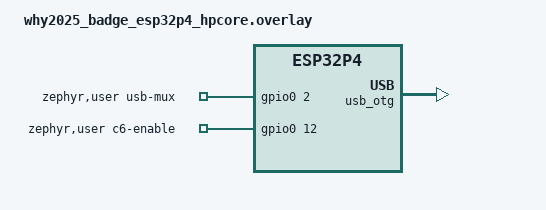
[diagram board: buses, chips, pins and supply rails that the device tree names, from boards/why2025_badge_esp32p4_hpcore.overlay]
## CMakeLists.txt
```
# SPDX-License-Identifier: GPL-3.0-or-later

cmake_minimum_required(VERSION 3.20.0)

find_package(Zephyr REQUIRED HINTS $ENV{ZEPHYR_BASE})
project(esp_sdr_pcap)

# USB: the CDC-ACM shell and DFU (app_usb.h); this app's vendor interface registers next to them.
include(${CMAKE_CURRENT_LIST_DIR}/../common/common.cmake)
# The radio over SDIO, the gapless stream's channelizer and the CPU clock, as the bridge has them.
include(${CMAKE_CURRENT_LIST_DIR}/../common/esdr_sdio_host.cmake)
include(${CMAKE_CURRENT_LIST_DIR}/../common/esdr_pfbq.cmake)
include(${CMAKE_CURRENT_LIST_DIR}/../common/app_clock.cmake)

target_include_directories(app PRIVATE src ../osmosdr/src ../../include ../ubertooth/src/upstream)
target_sources(app PRIVATE
  src/main.c
  src/radio.c
  src/survey.c
  src/narrow.c
  src/burst.c
  src/decoder.c
  src/output.c
  src/usb_pcap.c)

# The decoders and the stream's format: plain C, unit tested on native_sim (tests/unit/pcap_*,
# pcapng), at -O2 for their loops. The 802.15.4 PHY is lib/ieee802154's (no radio needed), the
# Bluetooth LE whitening and CRC the vendored Ubertooth tables (GPL-2.0-or-later).
set(PCAP_DSP
  src/follow.c
  src/pcapng.c
  src/records.c
  src/dec_ble.c
  src/dec_wpan.c
  src/dec_generic.c
  src/refine.c
  ${CMAKE_CURRENT_LIST_DIR}/../../lib/ieee802154/ieee154_phy.c
  ${CMAKE_CURRENT_LIST_DIR}/../ubertooth/src/upstream/bluetooth_le.c)
target_sources(app PRIVATE ${PCAP_DSP})
set_source_files_properties(${PCAP_DSP} PROPERTIES COMPILE_OPTIONS "-O2")
# The stream thread's work per sample (the channel mode's detector, the survey's assembler).
set_source_files_properties(src/narrow.c src/survey.c PROPERTIES COMPILE_OPTIONS "-O2")
```

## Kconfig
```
# SPDX-License-Identifier: GPL-3.0-or-later

mainmenu "ESP-SDR pcap"

menu "ESP-SDR pcap"

config APP_PCAP_BURSTS
	int "Burst buffers"
	default 48
	help
	  Buffers of a burst's samples (BURST_MAX_SAMPLES int16 pairs, 128 KiB
	  each) in PSRAM: bursts the channelizer assembles and the decoder has
	  yet to take.

config APP_PCAP_STREAM_CPU
	int "CPU of the stream thread"
	range 0 1
	default 1
	depends on SMP
	help
	  The channelizer's PIE state is per core and not saved on a
	  context switch: the stream thread is pinned before it starts.
	  The radio reader, USB, the shell and the work queues stay on
	  CPU 0 (SCHED_CPU_MASK_PIN_ONLY), where the interrupts and the
	  tick are. With the stream alone on CPU 1 and the decoders on
	  CPU 0, a 40 MS/s survey lost no bursts; the other way round the
	  reader and the stream overloaded CPU 0 (doc/pcap.md).

config APP_PCAP_DECODE_CPU
	int "CPU of the decoder and the generic analysis"
	range 0 1
	default 0
	depends on SMP

config APP_PCAP_GEN_WORKERS
	int "Generic analysis workers"
	range 1 2
	default 2 if SMP
	default 1
	help
	  Threads that analyse the bursts no decoder claimed, at the
	  lowest priority. The second is pinned to the stream thread's
	  CPU and takes the time the stream leaves there.

endmenu

rsource "../common/Kconfig"

# The USB device's identity (sample_usbd).
source "samples/subsys/usb/common/Kconfig.sample_usbd"

source "Kconfig.zephyr"
```

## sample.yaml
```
sample:
  name: ESP-SDR pcap
  description: >-
    An ESP32-P4 (WHY2025 badge, ESP32-P4-Function-EV-Board) demodulates and decodes the bursts
    its ESP32-C6 radio receives (Bluetooth LE, IEEE 802.15.4, any other as a burst record with
    its metadata) and streams them as pcapng over USB for Wireshark
common:
  tags: esp-sdr
  sysbuild: true
  platform_allow:
    - why2025_badge/esp32p4/hpcore
    - esp32p4_function_ev_board/esp32p4/hpcore
  integration_platforms:
    - why2025_badge/esp32p4/hpcore
    - esp32p4_function_ev_board/esp32p4/hpcore
tests:
  esp_sdr.pcap:
    build_only: true
```

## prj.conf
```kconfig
# SPDX-License-Identifier: GPL-3.0-or-later
#
# The ESP32-P4 as a burst sniffer: its ESP32-C6 radio over SDIO, the decoders, pcapng over USB.

CONFIG_GPIO=y
CONFIG_SDHC=y
CONFIG_SDIO_STACK=y
# The SDIO reader polls the radio's byte counter; idle, it sleeps a tick (100 us).
CONFIG_SYS_CLOCK_TICKS_PER_SEC=10000

# The decoders' floats; the burst buffers and scratch in PSRAM.
CONFIG_FPU=y
CONFIG_ESP_SPIRAM=y
CONFIG_HEAP_MEM_POOL_SIZE=16384
CONFIG_MAIN_STACK_SIZE=4096

# USB device on the OTG HS port: the shell on CDC-ACM, DFU with sysbuild/MCUboot, the pcapng
# stream on a vendor bulk IN endpoint (src/usb_pcap.c). Same PID as the other apps (host udev
# rules, west dfu); the host tool finds it by its product string.
CONFIG_USB_DEVICE_STACK_NEXT=y
CONFIG_UDC_DRIVER_HIGH_SPEED_SUPPORT_ENABLED=y
CONFIG_SAMPLE_USBD_PRODUCT="ESP-SDR pcap"
CONFIG_SAMPLE_USBD_PID=0x0005
CONFIG_USBD_LOG_LEVEL_WRN=y
CONFIG_UDC_DRIVER_LOG_LEVEL_WRN=y
CONFIG_USBD_CDC_ACM_CLASS=y
CONFIG_CDC_ACM_SERIAL_INITIALIZE_AT_BOOT=n
CONFIG_UART_LINE_CTRL=y
CONFIG_HWINFO=y
# Vendor requests wait for the radio's reply over SDIO in the USB thread.
CONFIG_USBD_THREAD_STACK_SIZE=4096
# The USB threads preempt the decoder where they share a core, not the system work queue that
# feeds the liveness watchdog (as in apps/micropython on the P4).
CONFIG_USBD_THREAD_PREEMPTIBLE=y
CONFIG_UDC_DWC2_THREAD_PREEMPTIBLE=y
# Below the stream thread (5) and the control queue (6), above the decoder (8): a long decode
# does not hold the stream's transfers back (on one core; with two the decoder has its own).
CONFIG_USBD_THREAD_PRIORITY=7
CONFIG_UDC_DWC2_THREAD_PRIORITY=7
CONFIG_USBD_DFU_TRANSFER_SIZE=1024
CONFIG_UDC_BUF_POOL_SIZE=4096

# The shell on CDC-ACM (west dfu confirms images with "mcuboot confirm"), logs on the console
# UART (the CH340 on the WHY2025 badge).
CONFIG_SHELL=y
CONFIG_SHELL_BACKEND_SERIAL=y
CONFIG_SHELL_LOG_BACKEND=n
CONFIG_SHELL_STACK_SIZE=3072
CONFIG_KERNEL_SHELL=y
CONFIG_MCUBOOT_SHELL=y
CONFIG_DEVICE_SHELL=n
CONFIG_DATE_SHELL=n
CONFIG_APP_LIVENESS_WATCHDOG=y
CONFIG_LOG=y
CONFIG_CBPRINTF_FP_SUPPORT=y
```

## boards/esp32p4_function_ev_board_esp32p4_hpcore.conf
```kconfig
# SPDX-License-Identifier: GPL-3.0-or-later
#
# The ESP32-P4-Function-EV-Board's default revision declares 8 MB of PSRAM (the V1.0B engineering
# board, revision 1.0.0, has 32): 32 burst buffers (4 MB) leave room for the PSRAM heap.
CONFIG_APP_PCAP_BURSTS=32
```

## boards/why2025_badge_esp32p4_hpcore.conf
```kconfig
# SPDX-License-Identifier: GPL-3.0-or-later
#
# The WHY2025 badge's 32 MB of PSRAM: 128 burst buffers (16 MB). The survey's 40 channels hold
# one each while open and the channelizer can keep the decoder waiting for some 12 ms (the radio's
# block pool), during which a busy band opens a few dozen bursts.
CONFIG_APP_PCAP_BURSTS=128

# Both HP cores (doc/pcap.md, "The P4"): CPU 1 the stream thread (channelizer, PIE) and a second
# generic analysis worker below it, CPU 0 the rest (the reader, USB, the decoders, the shell, the
# work queues). Pin-only: a thread nobody pins stays on CPU 0; IPIs only to the core a woken
# thread may run on.
CONFIG_SMP=y
CONFIG_SCHED_CPU_MASK=y
CONFIG_SCHED_CPU_MASK_PIN_ONLY=y
CONFIG_IPI_OPTIMIZE=y
```

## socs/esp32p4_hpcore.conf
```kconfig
# SPDX-License-Identifier: GPL-3.0-or-later
#
# The SoC turns the FPU on without sharing: the decoder thread, the channelizer and the shell
# (its float statistics) would clobber each other's float registers. Lazy switching (Zephyr
# decodes the trapping instruction from mtval, which the P4 fills).
CONFIG_FPU_SHARING=y
```

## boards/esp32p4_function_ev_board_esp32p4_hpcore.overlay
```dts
/*
 * SPDX-License-Identifier: GPL-3.0-or-later
 *
 * The ESP32-P4-Function-EV-Board's ESP32-P4: its USB 2.0 OTG HS port (USB-C) with the shell on
 * CDC-ACM, DFU and the pcapng stream; the C6 on sdhc1 (apps/osmosdr_serial with
 * CONFIG_APP_LINK_SDIO, installed by apps/c6_bootstrap).
 */

/ {
	chosen {
		esdr,link-sdio = &sdhc1;
		zephyr,shell-uart = &cdc_acm_uart0;
	};

	/* GPIO54 is the ESP32-C6's enable. */
	zephyr,user {
		c6-enable-gpios = <&gpio1 22 GPIO_ACTIVE_HIGH>;
	};
};

&esp_hosted_mcu {
	status = "disabled";
};

zephyr_udc0: &usb_otg {
	status = "okay";
	/*
	 * An IN endpoint is bulk capable only with a FIFO of a whole high-speed packet (512 bytes,
	 * 128 words). The endpoints take the FIFOs in order: CDC-ACM's notification endpoint the
	 * first (16 words, its packets are short), its data endpoint the second, the pcapng stream
	 * the third. With the RX FIFO (256) and EP0's (32) that is 816 of the controller's 896
	 * words (GHWCFG3), where three FIFOs of 128 would not fit.
	 */
	g-tx-fifo-size = <16 128 128 64 64 64 64>;

	cdc_acm_uart0: cdc_acm_uart0 {
		compatible = "zephyr,cdc-acm-uart";
		label = "ESP-SDR pcap shell";
	};
};

#include "../../micropython/boards/partitions_p4.dtsi"
```

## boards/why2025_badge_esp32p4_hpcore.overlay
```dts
/*
 * SPDX-License-Identifier: GPL-3.0-or-later
 *
 * The WHY2025 badge's ESP32-P4: USB-C port J8 on its OTG HS controller (GPIO2 low, the board's
 * default) with the shell on CDC-ACM, DFU and the pcapng stream; boot messages and logs on the
 * CH340 (UART0); the C6 on sdhc1 (apps/osmosdr_serial, gapless by default on this board).
 */

/ {
	chosen {
		esdr,link-sdio = &sdhc1;
		zephyr,shell-uart = &cdc_acm_uart0;
	};

	/* GPIO2 hands USB-C port J8 to the ESP32-C6; GPIO12 is its enable. */
	zephyr,user {
		usb-mux-gpios = <&gpio0 2 GPIO_ACTIVE_HIGH>;
		c6-enable-gpios = <&gpio0 12 GPIO_ACTIVE_HIGH>;
	};
};

/* The ESP32-C6 runs the radio firmware, not esp-hosted, whose driver would reset it. */
&esp_hosted_mcu {
	status = "disabled";
};

zephyr_udc0: &usb_otg {
	status = "okay";
	/*
	 * An IN endpoint is bulk capable only with a FIFO of a whole high-speed packet (512 bytes,
	 * 128 words). The endpoints take the FIFOs in order: CDC-ACM's notification endpoint the
	 * first (16 words, its packets are short), its data endpoint the second, the pcapng stream
	 * the third. With the RX FIFO (256) and EP0's (32) that is 816 of the controller's 896
	 * words (GHWCFG3), where three FIFOs of 128 would not fit.
	 */
	g-tx-fifo-size = <16 128 128 64 64 64 64>;

	cdc_acm_uart0: cdc_acm_uart0 {
		compatible = "zephyr,cdc-acm-uart";
		label = "ESP-SDR pcap shell";
	};
};

#include "../../micropython/boards/partitions_p4.dtsi"
```

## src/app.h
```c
/*
 * SPDX-License-Identifier: GPL-3.0-or-later
 *
 * What the parts of apps/pcap share (doc/pcap.md): the capture's settings, the time base, the
 * burst pool and the decoder's queue, the counters. main.c owns the settings and changes them
 * only while no capture runs.
 */

#ifndef APP_H_
#define APP_H_

#include <stdbool.h>
#include <stdint.h>

#include "burst.h"
#include "esdr_proto.h"
#include "pcap_proto.h"

/* The capture's settings: what the host or the shell set, taken at each start. */
struct app_cfg {
	/* enum pcap_mode and PCAP_MODE_F_*; the alternation's dwell times (both 0: none). */
	uint16_t mode, mode_flags;
	uint32_t survey_ms, channel_ms;
	/* The survey's centre and the channel mode's frequency and rate, as asked for. */
	uint64_t survey_hz, channel_hz;
	uint32_t channel_rate_hz;
	/* Receive gain index or ESDR_GAIN_AUTO. */
	uint16_t rx_gain;
	/* The channelizer: M, the detector's opening ratio, the channels kept. */
	uint16_t channels;
	float open_ratio;
	uint32_t mask[3];
	/* The C6's gapless settings (ESDR_REQ_SET_GAPLESS as the host sent it). */
	struct esdr_gapless_cfg gapless;
	/* What runs over the bursts. */
	struct pcap_decoders dec;
};

extern struct app_cfg app_cfg;

/* ---- time ---- */

/* The host's time: nanoseconds since the Unix epoch now (PCAP_REQ_SET_TIME). */
void timebase_set(uint64_t epoch_ns);
/* A run's first block: its time on the stream's axis (ns) is now. */
void timebase_anchor(uint64_t axis_ns);
/* The host time of a time on the stream's axis (the radio's clock: 80 or 40 MS/s, or the
 * channel).
 */
uint64_t timebase_ns(uint64_t axis_ns);
/* The host time now. */
uint64_t timebase_now_ns(void);

/* Sample @p m of a stream at @p rate_hz on the axis, ns (the rates divide 10^9). */
static inline uint64_t axis_ns(uint64_t m, uint32_t rate_hz)
{
	return m * (1000000000U / rate_hz);
}

/* ---- the burst pool (burst.c) ---- */

/* A free burst with its buffer, NULL when none; back with burst_put(). Any thread. */
struct burst *burst_get(void);
void burst_put(struct burst *b);
uint32_t burst_free_count(void);

/* ---- the decoder (decoder.c) ---- */

void decoder_init(void);
/* A closed burst for the decoder: 0, or -ENOSPC (the caller still owns it). */
int decoder_put(struct burst *b);
/* A wideband burst the C6 reported (a run of its width records): its records' sums. */
struct wide_run {
	/* The radio's centre, and the run's first and last pair on its 80 MS/s axis. */
	uint64_t centre_hz;
	uint64_t index, end;
	float r1_i, r1_q;
	int16_t power_dbfs_x10;
	uint8_t gain;
	uint16_t records;
};
int decoder_put_wide(const struct wide_run *w);
/* Bursts queued and waiting. */
uint32_t decoder_backlog(void);
/*
 * Bluetooth LE access addresses the decoder looks for besides the advertising one
 * (PCAP_REQ_ADD_AA): @p op 0 adds @p aa with @p crc_init, 1 removes it, 2 forgets all (the
 * learnt ones too). 0, -ENOSPC or -EINVAL.
 */
int decoder_aa(uint16_t op, uint32_t aa, uint32_t crc_init);

/* ---- the stream thread and its modes (survey.c, narrow.c) ---- */

/*
 * The stream thread to the survey of the gapless segments around @p centre_hz (the radio's
 * centre) at @p in_rate_hz (the C6's rate: ESDR_GAPLESS_RATE_HZ, or half with
 * ESDR_GAPLESS_F_HALF), to the channel mode at @p freq_hz and @p rate_hz, or to idle; what was
 * open goes to the decoder, cut. Called from the control thread: they wait for the stream
 * thread. 0 or a negative errno.
 */
int survey_start(uint64_t centre_hz, uint32_t in_rate_hz);
/* Whether the survey can run its bank at @p in_rate_hz: 0, -EINVAL or -ENOMEM. */
int survey_check(uint32_t in_rate_hz);
int stream_narrow(uint64_t freq_hz, uint32_t rate_hz);
void survey_stop(void);
/* The radio's sink (radio.h) while a mode runs. */
void survey_block(uint8_t *blk);

/* The channel mode's parts, run by the stream thread (narrow.c). */
int narrow_start(uint64_t freq_hz, uint32_t rate_hz);
void narrow_stop(void);
void narrow_block(const uint8_t *blk);

/* ---- the follow mode (main.c) ---- */

/*
 * The decoder thread found 802.15.4 on @p channel, worth @p points (follow.h), in a burst of the
 * survey or of the channel mode. Nothing unless the capture follows.
 */
void follow_report(int channel, uint32_t points, bool from_survey);

/* ---- counters ---- */

/* Generic analysis workers (decoder.c): a second one goes on the stream's core. */
#define APP_GEN_WORKERS CONFIG_APP_PCAP_GEN_WORKERS

struct app_stats {
	uint32_t seg_blocks, seg_dropped, other_blocks;
	uint64_t pairs, chan_cycles;
	uint32_t bursts, bursts_lost, bursts_wide;
	uint32_t decoded;
	uint64_t dec_cycles;
	uint64_t channel_samples;
	uint32_t channel_gaps, c6_wide;
	/* generic and generic_cycles per worker: one writer each. */
	uint32_t generic[APP_GEN_WORKERS], generic_skipped, generic_wide;
	uint64_t generic_cycles[APP_GEN_WORKERS];
	/* The follow mode: the survey's sightings per channel (11 to 26), stays on a channel. */
	uint32_t follow_sights[16], follow_hops;
};

extern struct app_stats app_stats;

#endif /* APP_H_ */
```

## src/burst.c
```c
/*
 * SPDX-License-Identifier: GPL-3.0-or-later
 *
 * The burst pool (app.h): CONFIG_APP_PCAP_BURSTS buffers of BURST_MAX_SAMPLES int16 pairs in
 * PSRAM, handed out by a queue of the free ones.
 */

#include <zephyr/kernel.h>

#include "app.h"
#include "dec_util.h"

/* PSRAM: EXT_RAM_BSS_ATTR is empty on the ESP32-P4, whose linker script still puts the section
 * there (apps/micropython/cmod/esdr_defs.h).
 */
#define PSRAM __attribute__((section(".ext_ram.bss")))

static int16_t mem[CONFIG_APP_PCAP_BURSTS][2U * BURST_MAX_SAMPLES] __aligned(16) PSRAM;
static struct burst bursts[CONFIG_APP_PCAP_BURSTS];
K_MSGQ_DEFINE(free_q, sizeof(struct burst *), CONFIG_APP_PCAP_BURSTS, 4);

struct burst *burst_get(void)
{
	struct burst *b;

	if (k_msgq_get(&free_q, &b, K_NO_WAIT) != 0) {
		return NULL;
	}
	*b = (struct burst){.iq = b->iq};
	return b;
}

void burst_put(struct burst *b)
{
	(void)k_msgq_put(&free_q, &b, K_NO_WAIT);
}

uint32_t burst_free_count(void)
{
	return k_msgq_num_used_get(&free_q);
}

int16_t burst_dbfs_x10(float power)
{
	return dec_dbfs_x10(power);
}

static int burst_pool_init(void)
{
	for (unsigned int i = 0; i < CONFIG_APP_PCAP_BURSTS; i++) {
		struct burst *b = &bursts[i];

		b->iq = mem[i];
		(void)k_msgq_put(&free_q, &b, K_NO_WAIT);
	}
	return 0;
}
SYS_INIT(burst_pool_init, APPLICATION, 0);
```

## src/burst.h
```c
/*
 * SPDX-License-Identifier: GPL-3.0-or-later
 *
 * A burst: one channel's samples from the detector's opening to its closing (doc/pcap.md).
 * The assembler (burst.c, the channelizer thread) fills one from the detector's events; the
 * decoder thread reads it. Plain C: the decoders and their tests on native_sim use this header
 * without Zephyr.
 */

#ifndef BURST_H_
#define BURST_H_

#include <stdbool.h>
#include <stddef.h>
#include <stdint.h>

/* Frames (complex samples) a burst holds at most: 8.2 ms at 4 MS/s. */
#define BURST_MAX_SAMPLES 32768U
/* Adjacent channels open at once that make a wideband signal (the pool's size is
 * CONFIG_APP_PCAP_BURSTS). */
#define BURST_WIDE_MIN 6U

/* struct burst.flags */
/* Cut at BURST_MAX_SAMPLES while the channel stayed open. */
#define BURST_F_TRUNCATED 0x0001U
/* Part of a wideband signal: no samples kept (n is 0), only the metadata. */
#define BURST_F_WIDEBAND  0x0002U
/* Frames of the filterbank's transient among the samples (a gap in the input). */
#define BURST_F_TRANSIENT 0x0004U
/* A neighbouring channel was open at the same time. */
#define BURST_F_NEIGHBOUR 0x0008U
/* The C6 dropped windows before this burst (ESDR_SEG_DROPPED). */
#define BURST_F_DROPPED   0x0010U
/* Samples at the receiver's full scale. */
#define BURST_F_CLIPPED   0x0020U
/* Still open when the capture stopped. */
#define BURST_F_CUT       0x0040U
/* Ended at a hole in the radio's stream (the C6 kept nothing for a while): what follows is
 * another burst. */
#define BURST_F_HOLE      0x0080U
/* A decoder emitted a packet from it (the decoder thread's: no generic analysis follows). */
#define BURST_F_CLAIMED   0x0100U
/* gate_snr and gate_narrow are set (the decoder thread's). */
#define BURST_F_GATED     0x0200U

struct burst {
	/* The channelizer's channel index and count, the channel's rate and centre frequency. */
	uint16_t chan, channels;
	uint32_t rate_hz;
	uint64_t freq_hz;
	/*
	 * The first sample's frame index on the channel's absolute grid (its pair index is
	 * m0 * D, D = channels / 2, on the C6's axis: 80 MS/s, or 40 with ESDR_GAPLESS_F_HALF): the
	 * decoders and the combination of two neighbours go by it.
	 */
	uint64_t m0;
	/* Samples in iq (frames), their first and last one that the detector found loud. */
	uint32_t n, loud_from, loud_to;
	/* The detector's floor and the highest block power of the burst, output units squared
	 * (a full-scale carrier, 512 raw units, is 16384 in the samples: 16384^2 here). */
	float floor, power;
	/* BURST_F_* */
	uint16_t flags;
	/* Receive gain index of the segment that opened it (ESDR_SEG_GAIN_AUTO: automatic). */
	uint8_t gain;
	/* Reference count, the decoder thread's (a burst held for its neighbour). */
	uint8_t ref;
	/* For wideband bursts: the lowest and highest adjacent channel open with this one. */
	uint16_t wide_lo, wide_hi;
	/* The decoder thread's look at the loud part (BURST_F_GATED): power above the floor over
	 * the floor, the correlation one sample apart over that power. */
	float gate_snr, gate_narrow;
	/* n interleaved I, Q samples, 4-byte aligned, in the pool's buffer. */
	int16_t *iq;
};

/* dB relative to the receiver's full scale, times 10, of a power in output units squared. */
int16_t burst_dbfs_x10(float power);

#endif /* BURST_H_ */
```

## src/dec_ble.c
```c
/*
 * SPDX-License-Identifier: GPL-3.0-or-later
 *
 * The Bluetooth LE decoder of apps/pcap (decode.h, doc/pcap.md "Decoders"): LE 1M and LE 2M
 * packets in a closed burst at 4 or 2 MS/s, the algorithm of apps/chancap/tools/ble_pcap.py. An
 * FM discriminator (dec_step(), a binary angle a sample) summed over a symbol at every sampling
 * phase, the access addresses looked for at every position whatever the carrier offset, the
 * bits sliced at the preamble's level, dewhitened and CRC checked with the vendored upstream
 * apps/ubertooth/src/upstream/bluetooth_le.c (its directory on the include path, its source
 * linked in). Plain C, no Zephyr: tests/unit/pcap_ble runs it on native_sim.
 *
 * The search runs per sampling phase, in sample order, in two steps. The coarse step, at every
 * position (of every other phase at 4 samples a symbol): each soft symbol sliced once against
 * the mean of the 32 symbols from it on (all of them signal where an access address starts up
 * to 31 symbols before, whatever precedes the packet), the last 32 decisions compared with
 * every address. Where an address comes within max_errors + GATE_SLACK bits (and
 * |ones - zeros| / 8 more for an unbalanced one), the fine step is ble_pcap.py's find_aa() at
 * the positions from there to one symbol past the first match: the normalised correlation of
 * the 32 soft symbols with the address's +-1 pattern and their bit errors against the window's
 * own midpoint. The best match with at most max_errors errors is taken (fewest errors, then
 * highest correlation). Matches are taken in time order: ble_pcap.py takes the best match of
 * the whole rest of a capture, which can skip a packet before a better one.
 */

#include <errno.h>
#include <stdbool.h>
#include <stdint.h>
#include <string.h>

#include "bluetooth_le.h"
#include "dec_util.h"
#include "decode.h"

#define SYM_RATE_1M 1000000U
#define SYM_RATE_2M 2000000U

/* Symbols of the preambles, of the access address, and of the shortest packet after the
 * preamble (address, PDU header, CRC). */
#define PRE_1M     8U
#define PRE_2M     16U
#define AA_SYMS    32U
#define MIN_SYMS   (32U + 16U + 24U)
/* Preamble symbols before the address whose mean is the slicing level: alternating, so the
 * Gaussian filter's intersymbol interference cancels. */
#define LEVEL_SYMS 6U
/* The coarse step's bit errors beyond max_errors (its level is not the window's midpoint). */
#define GATE_SLACK 4U

/* Longer bursts are refused: sample indices stay well within 32 bits. */
#define N_MAX (1U << 24)

/* The RF channels: 2402 MHz + 2 MHz c for c = 0 .. 39, a frequency within 500 kHz. */
#define RF_BASE_HZ 2402000000LL
#define RF_STEP_HZ 2000000LL
#define RF_TOL_HZ  500000LL
#define RF_COUNT   40

/* CONNECT_IND: advertising PDU type 5, a payload of InitA, AdvA and 22 bytes of LLData whose
 * access address and CRCInit sit at these offsets of dec_ble_pkt.air (ubt_le.h). */
#define PDU_CONNECT_IND 5U
#define CONNECT_LEN     34U
#define AIR_CONN_AA     18U
#define AIR_CONN_CRC    22U

/*
 * LE 1M packets whose samples LE 2M skips, at most: one takes 80 symbols or more, 320 samples
 * at 4 MS/s (the only rate with LE 2M).
 */
#define CLAIMS(n) ((n) / 256U + 2U)

/* A configured access address as the search uses it. */
struct pat {
	uint32_t aa;
	uint32_t crc_init;
	/* Its ones, zeros, ones - zeros, and 1024 - (ones - zeros)^2 (32^2 / 32 times the
	 * variance of its +-1 pattern). */
	int32_t n1, n0, psum;
	int64_t varp;
	/* The coarse step's bit errors at most. */
	uint32_t gate;
};

/* One PHY's view of the burst: the symbol sums per sampling phase. */
struct pass {
	const int16_t *s[4];
	uint32_t k[4];
	uint32_t sps;
	uint32_t pre;
	uint32_t sym_rate;
	enum dec_ble_phy phy;
};

/* Samples [from, to) of an LE 1M packet: LE 2M looks for nothing there. */
struct claim {
	int32_t from, to;
};

struct ctx {
	const struct burst *b;
	const struct dec_ble_cfg *cfg;
	struct pat pat[DEC_BLE_AA_MAX];
	unsigned int npat;
	/* The channel's centre, MHz, for le_dewhiten(). */
	unsigned int mhz;
	/* n binary angles (the last one 0), n symbol sums, the claims. */
	int16_t *d;
	int16_t *sums;
	struct claim *claims;
	uint32_t nclaims, claims_max;
	dec_ble_emit emit;
	void *user;
	int count;
};

/* A position the fine step accepted: phase, symbol, address, bit errors, correlation (Q14). */
struct match {
	uint32_t p, k;
	const struct pat *pat;
	uint32_t errors;
	int32_t r;
};

/* In the coarse step's loop: inline at -Os too. */
static inline __attribute__((always_inline)) uint32_t popcount32(uint32_t v)
{
	v = v - ((v >> 1) & 0x55555555U);
	v = (v & 0x33333333U) + ((v >> 2) & 0x33333333U);
	v = (v + (v >> 4)) & 0x0F0F0F0FU;
	return (v * 0x01010101U) >> 24;
}

/* CRCInit as the CONNECT_IND carries it to the start state of btle_crcgen_lut(): bit reversed. */
static uint32_t rev24(uint32_t v)
{
	uint32_t r = 0;

	for (unsigned int i = 0; i < 24U; i++) {
		r |= ((v >> i) & 1U) << (23U - i);
	}
	return r;
}

static uint32_t isqrt64(uint64_t v)
{
	uint64_t r = 0, bit = 1ULL << 62;

	while (bit > v) {
		bit >>= 2;
	}
	while (bit != 0U) {
		if (v >= r + bit) {
			v -= r + bit;
			r = (r >> 1) + bit;
		} else {
			r >>= 1;
		}
		bit >>= 2;
	}
	return (uint32_t)r;
}

int dec_ble_rf_channel(uint64_t freq_hz)
{
	int64_t d, c, dev;

	if (freq_hz > (uint64_t)INT64_MAX / 2U) {
		return -1;
	}
	d = (int64_t)freq_hz - RF_BASE_HZ + RF_STEP_HZ / 2;
	if (d < 0) {
		return -1;
	}
	c = d / RF_STEP_HZ;
	dev = d - c * RF_STEP_HZ - RF_STEP_HZ / 2;
	if (c >= RF_COUNT || dev <= -RF_TOL_HZ || dev >= RF_TOL_HZ) {
		return -1;
	}
	return (int)c;
}

size_t dec_ble_scratch(uint32_t n)
{
	/* Alignment, the claims, the angles and the symbol sums. */
	return 4U + (size_t)CLAIMS(n) * sizeof(struct claim) + 2U * (size_t)n * sizeof(int16_t);
}

static unsigned int patterns(const struct dec_ble_cfg *cfg, struct pat *pt)
{
	unsigned int n = 0;

	for (unsigned int i = 0; i < cfg->aa_count; i++) {
		int32_t ones = (int32_t)popcount32(cfg->aa[i].aa);
		int32_t psum = 2 * ones - 32;

		/* A constant pattern correlates with nothing. */
		if (ones == 0 || ones == 32) {
			continue;
		}
		pt[n].aa = cfg->aa[i].aa;
		pt[n].crc_init = cfg->aa[i].crc_init & 0xFFFFFFU;
		pt[n].n1 = ones;
		pt[n].n0 = 32 - ones;
		pt[n].psum = psum;
		pt[n].varp = 1024 - psum * psum;
		pt[n].gate =
			cfg->max_errors + GATE_SLACK + (uint32_t)(psum < 0 ? -psum : psum) / 8U;
		n++;
	}
	return n;
}

/* The phase step from every sample to the next: one dec_step() a sample. */
static void angles(const struct burst *b, int16_t *d)
{
	const int16_t *iq = b->iq;
	uint32_t i;

	for (i = 0; i + 1U < b->n; i++, iq += 2) {
		/* +pi (32768) wraps to -pi: the same angle. */
		d[i] = (int16_t)dec_step(iq[0], iq[1], iq[2], iq[3]);
	}
	d[b->n - 1U] = 0;
}

/*
 * ble_pcap.py's symbol_sums() and phase split: the angles summed over a symbol (sps of them)
 * from every sample on, divided by sps (rounded, to stay within int16), the sums of the
 * samples p, p + sps, p + 2 sps, ... in a row for phase p.
 */
static void symbol_sums(struct ctx *c, struct pass *ps)
{
	const uint32_t sps = ps->sps;
	const uint32_t shift = sps == 4U ? 2U : 1U;
	const int32_t half = (int32_t)(sps >> 1);
	const uint32_t total = c->b->n - sps;
	const uint32_t stride = (total + sps - 1U) / sps;
	const int16_t *d = c->d;
	int16_t *const sums = c->sums;
	int32_t run = 0;
	uint32_t i, j, k, p;

	for (p = 0; p < sps; p++) {
		ps->s[p] = sums + p * stride;
		ps->k[p] = total > p ? (total - p + sps - 1U) / sps : 0U;
	}
	for (i = 0; i < sps; i++) {
		run += d[i];
	}
	for (j = 0, k = 0; j < total; k++) {
		for (p = 0; p < sps && j < total; p++, j++) {
			sums[p * stride + k] = (int16_t)((run + half) >> shift);
			run += d[j + sps] - d[j];
		}
	}
}

/*
 * find_aa() at one position: the normalised correlation (Q14) of the 32 soft symbols from @p s
 * with the address's +-1 pattern, and the bit errors against the window's own midpoint (the
 * middle between the mean of the symbols where the address has ones and that where it has
 * zeros), returned. A flat window matches nothing.
 */
static uint32_t exact(const int16_t *s, const struct pat *pt, int32_t *r)
{
	int32_t s1 = 0, a1 = 0, a0, num, den;
	int64_t s2 = 0, c, var;
	uint32_t errors = 0, i;

	for (i = 0; i < AA_SYMS; i++) {
		int32_t v = s[i];

		s1 += v;
		s2 += (int64_t)v * v;
		if (((pt->aa >> i) & 1U) != 0U) {
			a1 += v;
		}
	}
	var = 32 * s2 - (int64_t)s1 * s1;
	if (var <= 0) {
		*r = 0;
		return AA_SYMS;
	}
	a0 = s1 - a1;
	c = 32 * (int64_t)(a1 - a0) - (int64_t)pt->psum * s1;
	*r = (int32_t)(c * 16384 / (int64_t)isqrt64((uint64_t)var * (uint64_t)pt->varp));
	num = a1 * pt->n0 + a0 * pt->n1;
	den = 2 * pt->n1 * pt->n0;
	for (i = 0; i < AA_SYMS; i++) {
		errors += (uint32_t)(s[i] * den > num) ^ ((pt->aa >> i) & 1U);
	}
	return errors;
}

/*
 * The fine step from sample position @p x0 (phase x0 % sps, symbol x0 / sps) to one symbol past
 * the first position that matches; positions up to @p done were looked at before. True with
 * the best match in @p best.
 */
static bool fine(const struct ctx *c, const struct pass *ps, int32_t x0, uint32_t k0min,
		 int32_t *done, struct match *best)
{
	const int32_t sps = (int32_t)ps->sps;
	int32_t x = x0 > *done ? x0 : *done + 1;
	int32_t xend = x0 + sps - 1;
	bool found = false;

	for (; x <= xend; x++) {
		uint32_t p = (uint32_t)x % ps->sps, k = (uint32_t)x / ps->sps;

		*done = x;
		if (k < k0min || ps->k[p] < MIN_SYMS || k > ps->k[p] - MIN_SYMS) {
			continue;
		}
		for (unsigned int j = 0; j < c->npat; j++) {
			int32_t r;
			uint32_t e = exact(ps->s[p] + k, &c->pat[j], &r);

			if (e > c->cfg->max_errors) {
				continue;
			}
			if (!found) {
				xend = x + sps - 1;
			}
			if (!found || e < best->errors || (e == best->errors && r > best->r)) {
				best->p = p;
				best->k = k;
				best->pat = &c->pat[j];
				best->errors = e;
				best->r = r;
				found = true;
			}
		}
	}
	return found;
}

/*
 * @p nbytes bytes of the symbols from @p s, a one where a symbol lies above the level
 * num / den, the first symbol on air in each byte's bit 7 (as le_dewhiten() takes them).
 */
static void slice(const int16_t *s, int32_t num, int32_t den, uint8_t *out, uint32_t nbytes)
{
	for (uint32_t i = 0; i < nbytes; i++, s += 8) {
		uint32_t v = 0;

		for (uint32_t j = 0; j < 8U; j++) {
			v = (v << 1) | (uint32_t)(s[j] * den > num);
		}
		out[i] = (uint8_t)v;
	}
}

/* Mean I^2 + Q^2 over samples [from, to) of the burst. */
static float power(const struct burst *b, int32_t from, int32_t to)
{
	uint64_t acc = 0;

	if (from < 0) {
		from = 0;
	}
	if (to > (int32_t)b->n) {
		to = (int32_t)b->n;
	}
	if (to <= from) {
		return 0.0f;
	}
	for (int32_t i = from; i < to; i++) {
		int32_t vi = b->iq[2 * i], vq = b->iq[2 * i + 1];

		acc += (uint32_t)(vi * vi) + (uint32_t)(vq * vq);
	}
	return (float)acc / (float)(to - from);
}

static uint32_t le_get(const uint8_t *p, unsigned int bytes)
{
	uint32_t v = 0;

	for (unsigned int i = 0; i < bytes; i++) {
		v |= (uint32_t)p[i] << (8U * i);
	}
	return v;
}

/*
 * The packet whose access address the fine step found: sliced at the mean of the preamble's
 * last LEVEL_SYMS symbols (at the window's midpoint without room for them), the header
 * dewhitened for the length, then all of it; the CRC checked, the packet emitted unless its
 * CRC failed and bad ones are not kept. Returns the symbol the search goes on from: after the
 * packet, or after the address when the CRC failed (its length is not to be trusted) or the
 * burst ends before the packet does (ble_pcap.py's decode()).
 */
static uint32_t decode(struct ctx *c, const struct pass *ps, const struct match *m)
{
	const struct pat *pt = m->pat;
	const int16_t *s = ps->s[m->p] + m->k;
	const uint32_t avail = ps->k[m->p] - m->k;
	const uint32_t sps = ps->sps;
	struct dec_ble_pkt pkt;
	int32_t num = 0, den, x, end;
	uint32_t rx = 0, len, nbytes, i;
	uint8_t hdr[2];
	bool trusted;

	if (m->k >= LEVEL_SYMS) {
		for (i = 1; i <= LEVEL_SYMS; i++) {
			num += s[-(int32_t)i];
		}
		den = (int32_t)LEVEL_SYMS;
	} else {
		int32_t a1 = 0, a0 = 0;

		for (i = 0; i < AA_SYMS; i++) {
			if (((pt->aa >> i) & 1U) != 0U) {
				a1 += s[i];
			} else {
				a0 += s[i];
			}
		}
		num = a1 * pt->n0 + a0 * pt->n1;
		den = 2 * pt->n1 * pt->n0;
	}
	for (i = 0; i < AA_SYMS; i++) {
		rx |= (uint32_t)(s[i] * den > num) << i;
	}
	slice(s + AA_SYMS, num, den, hdr, 2U);
	le_dewhiten(hdr, 2U, c->mhz);
	len = hdr[1];
	nbytes = 2U + len + 3U;
	if (AA_SYMS + 8U * nbytes > avail) {
		return m->k + AA_SYMS;
	}

	memset(&pkt, 0, sizeof(pkt));
	pkt.phy = ps->phy;
	pkt.aa = pt->aa;
	pkt.aa_errors = (uint8_t)popcount32(rx ^ pt->aa);
	for (i = 0; i < 4U; i++) {
		pkt.air[i] = (uint8_t)(pt->aa >> (8U * i));
	}
	slice(s + AA_SYMS, num, den, pkt.air + 4, nbytes);
	le_dewhiten(pkt.air + 4, nbytes, c->mhz);
	pkt.len = (uint16_t)(4U + nbytes);
	pkt.crc_checked = pt->crc_init != 0U;
	if (pkt.crc_checked) {
		pkt.crc_ok = btle_crcgen_lut(rev24(pt->crc_init), pkt.air + 4, (int)(2U + len)) ==
			     le_get(pkt.air + 6U + len, 3U);
	}
	x = (int32_t)(m->p + m->k * sps);
	pkt.start = x - (int32_t)(ps->pre * sps);
	end = x + (int32_t)((AA_SYMS + 8U * nbytes) * sps);
	/* The level is a mean angle a sample: times sps a symbol. */
	pkt.offset_hz = (int32_t)lrintf(
		dec_angle_hz((float)num / (float)den * (float)sps, (float)ps->sym_rate));
	pkt.power = power(c->b, pkt.start, end);
	if (pt->aa == DEC_BLE_ADV_AA && pkt.crc_ok && (pkt.air[4] & 0x0FU) == PDU_CONNECT_IND &&
	    len >= CONNECT_LEN) {
		pkt.conn_aa = le_get(pkt.air + AIR_CONN_AA, 4U);
		pkt.conn_crc_init = le_get(pkt.air + AIR_CONN_CRC, 3U);
	}

	trusted = !pkt.crc_checked || pkt.crc_ok;
	if (trusted && ps->phy == DEC_BLE_PHY_1M && c->nclaims < c->claims_max) {
		c->claims[c->nclaims].from = pkt.start;
		c->claims[c->nclaims].to = end;
		c->nclaims++;
	}
	if (trusted || c->cfg->keep_bad) {
		c->count++;
		if (c->emit != NULL) {
			c->emit(&pkt, c->user);
		}
	}
	return trusted ? m->k + AA_SYMS + 8U * nbytes : m->k + AA_SYMS;
}

/*
 * The coarse step of one sampling phase, resumable: the next symbol to push, the first push
 * that completes a window to test, the end (an address from symbol K - 72 on leaves no room
 * for a packet, so pushes stop at K - 41), the last 32 decisions (the newest in bit 31: the
 * address's bit 0, first on air, in bit 0), the sum of the 32 symbols from the next one on,
 * and the pending hit: the sample position of its window's first symbol, -1 for none.
 */
struct coarse {
	const int16_t *s;
	uint32_t p;
	uint32_t k, ktest, kend;
	uint32_t reg;
	int32_t fsum;
	int32_t hit;
};

static void coarse_start(struct coarse *cs, const struct pass *ps, uint32_t p, uint32_t k0)
{
	const uint32_t kn = ps->k[p];

	cs->s = ps->s[p];
	cs->p = p;
	cs->k = k0;
	cs->ktest = k0 + AA_SYMS - 1U;
	cs->kend = kn >= MIN_SYMS ? kn - (MIN_SYMS - AA_SYMS) : 0U;
	cs->reg = 0;
	cs->fsum = 0;
	cs->hit = -1;
	if (k0 < cs->kend) {
		for (uint32_t i = 0; i < AA_SYMS; i++) {
			cs->fsum += cs->s[k0 + i];
		}
	}
}

/* One symbol into the decisions: above the mean of the 32 from it on, or not. */
#define COARSE_PUSH()                                                                              \
	do {                                                                                       \
		int32_t v_ = s[k];                                                                 \
                                                                                                   \
		reg = (reg >> 1) | ((uint32_t)(32 * v_ > fsum) << 31);                             \
		fsum += s[k + AA_SYMS] - v_;                                                       \
		k++;                                                                               \
	} while (0)

/* The phase's next hit: the next window within an address's gate (cs->hit, -1 at the end). */
static void coarse_next(struct coarse *cs, const struct ctx *c, uint32_t sps)
{
	const int16_t *s = cs->s;
	const uint32_t kend = cs->kend;
	uint32_t k = cs->k, reg = cs->reg;
	int32_t fsum = cs->fsum;

	cs->hit = -1;
	while (k < kend && k < cs->ktest) {
		COARSE_PUSH();
	}
	if (c->npat == 1U) {
		const uint32_t aa = c->pat[0].aa, gate = c->pat[0].gate;

		while (k < kend) {
			COARSE_PUSH();
			if (popcount32(reg ^ aa) <= gate) {
				cs->hit = (int32_t)(cs->p + (k - AA_SYMS) * sps);
				break;
			}
		}
	} else {
		while (k < kend && cs->hit < 0) {
			COARSE_PUSH();
			for (unsigned int j = 0; j < c->npat; j++) {
				if (popcount32(reg ^ c->pat[j].aa) <= c->pat[j].gate) {
					cs->hit = (int32_t)(cs->p + (k - AA_SYMS) * sps);
					break;
				}
			}
		}
	}
	cs->k = k;
	cs->reg = reg;
	cs->fsum = fsum;
}

/* Every scanned phase from symbol @p k0 on, each to its first hit. */
static void coarse_restart(struct coarse *cs, uint32_t nc, uint32_t step, const struct ctx *c,
			   const struct pass *ps, uint32_t k0)
{
	for (uint32_t i = 0; i < nc; i++) {
		coarse_start(&cs[i], ps, i * step, k0);
		coarse_next(&cs[i], c, ps->sps);
	}
}

/*
 * Every packet of one PHY, in time order (see the top of the file): the phases' coarse hits
 * merged in sample order, the fine step at each. At 4 samples a symbol the coarse step scans
 * every other phase (a symbol sum one sample off the eye's centre still decides right) and the
 * fine step starts a sample before the hit.
 */
static void scan(struct ctx *c, const struct pass *ps)
{
	const uint32_t step = ps->sps == 4U ? 2U : 1U, nc = ps->sps / step;
	struct coarse cs[4];
	struct match m = {0};
	uint32_t k0min = 0, ci = 0;
	int32_t done = -1;

	coarse_restart(cs, nc, step, c, ps, 0U);
	for (;;) {
		uint32_t first = nc;
		int32_t x0;

		for (uint32_t i = 0; i < nc; i++) {
			if (cs[i].hit >= 0 && (first == nc || cs[i].hit < cs[first].hit)) {
				first = i;
			}
		}
		if (first == nc) {
			break;
		}
		x0 = cs[first].hit;
		if (ps->phy == DEC_BLE_PHY_2M) {
			while (ci < c->nclaims && c->claims[ci].to <= x0) {
				ci++;
			}
			if (ci < c->nclaims && c->claims[ci].from <= x0) {
				k0min = ((uint32_t)c->claims[ci].to + ps->sps - 1U) / ps->sps;
				coarse_restart(cs, nc, step, c, ps, k0min);
				continue;
			}
		}
		x0 -= (int32_t)(step - 1U);
		if (fine(c, ps, x0 > 0 ? x0 : 0, k0min, &done, &m)) {
			k0min = decode(c, ps, &m);
			coarse_restart(cs, nc, step, c, ps, k0min);
			continue;
		}
		coarse_next(&cs[first], c, ps->sps);
	}
}

int dec_ble_run(const struct burst *b, const struct dec_ble_cfg *cfg, void *scratch,
		size_t scratch_len, dec_ble_emit emit, void *user)
{
	struct ctx c;
	struct pass ps;
	int rf;

	if (b == NULL || cfg == NULL) {
		return -EINVAL;
	}
	if (b->rate_hz != 4000000U && b->rate_hz != 2000000U) {
		return -ENOTSUP;
	}
	if (cfg->aa_count > DEC_BLE_AA_MAX || cfg->max_errors > 2U || b->n > N_MAX ||
	    (b->n != 0U && b->iq == NULL)) {
		return -EINVAL;
	}
	/* Dewhitening needs the channel: a frequency off the grid is the caller's mistake. */
	rf = dec_ble_rf_channel(b->freq_hz);
	if (rf < 0) {
		return -EINVAL;
	}
	if (scratch == NULL || scratch_len < dec_ble_scratch(b->n)) {
		return -ENOMEM;
	}

	memset(&c, 0, sizeof(c));
	c.b = b;
	c.cfg = cfg;
	c.emit = emit;
	c.user = user;
	c.mhz = 2402U + 2U * (unsigned int)rf;
	c.npat = patterns(cfg, c.pat);
	/* Not even the shortest packet at 2 samples a symbol. */
	if (c.npat == 0U || b->n < 2U * MIN_SYMS) {
		return 0;
	}
	c.claims = (struct claim *)(((uintptr_t)scratch + 3U) & ~(uintptr_t)3U);
	c.claims_max = CLAIMS(b->n);
	c.d = (int16_t *)(c.claims + c.claims_max);
	c.sums = c.d + b->n;
	angles(b, c.d);

	if (!cfg->skip_1m) {
		ps.sps = b->rate_hz / SYM_RATE_1M;
		ps.pre = PRE_1M;
		ps.sym_rate = SYM_RATE_1M;
		ps.phy = DEC_BLE_PHY_1M;
		symbol_sums(&c, &ps);
		scan(&c, &ps);
	}

	if (cfg->phy_2m && b->rate_hz == 4000000U) {
		ps.sps = 2U;
		ps.pre = PRE_2M;
		ps.sym_rate = SYM_RATE_2M;
		ps.phy = DEC_BLE_PHY_2M;
		symbol_sums(&c, &ps);
		scan(&c, &ps);
	}
	return c.count;
}
```

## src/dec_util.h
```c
/*
 * SPDX-License-Identifier: GPL-3.0-or-later
 *
 * Small helpers the decoders share (decode.h): binary angles from int16 I/Q, dB scales. Plain
 * C, header only.
 */

#ifndef DEC_UTIL_H_
#define DEC_UTIL_H_

#include <math.h>
#include <stdint.h>

/* A full-scale carrier (512 raw units) in the channelizer's output: cfg.gain 32 times. */
#define DEC_FULL_SCALE 16384.0f

/*
 * atan2(im, re) as a binary angle, -32768 .. 32767 for -pi .. pi (65536 a turn), within 0.25
 * degrees; apps/micropython/cmod/esdr_fsk.c's esdr_fsk_angle(), inline for the decoders.
 */
static inline int32_t dec_angle(int32_t re, int32_t im)
{
	uint32_t ax = re >= 0 ? (uint32_t)re : -(uint32_t)re;
	uint32_t ay = im >= 0 ? (uint32_t)im : -(uint32_t)im;
	uint32_t mx = ax >= ay ? ax : ay, mn = ax >= ay ? ay : ax;
	int32_t a;

	if (mx == 0U) {
		return 0;
	}
	while (mx >= (1U << 19)) {
		mx >>= 4;
		mn >>= 4;
	}
	while (mx >= (1U << 15)) {
		mx >>= 1;
		mn >>= 1;
	}
	int32_t r = (int32_t)((mn << 15) / mx);

	a = (r >> 2) + ((((r * (32768 - r)) >> 15) * 2847) >> 15);
	if (ay > ax) {
		a = 16384 - a;
	}
	if (re < 0) {
		a = 32768 - a;
	}
	if (im < 0) {
		a = -a;
	}
	return a;
}

/*
 * The phase step from sample a to sample b (int16 I, Q): the angle of b conj(a), a binary angle.
 * The inputs are halved so that the products stay within 32 bits.
 */
static inline int32_t dec_step(int16_t ai, int16_t aq, int16_t bi, int16_t bq)
{
	int32_t pi = ai >> 1, pq = aq >> 1, i = bi >> 1, q = bq >> 1;

	return dec_angle(i * pi + q * pq, q * pi - i * pq);
}

/* A binary angle a sample (or a symbol) as a frequency, Hz, at @p rate samples (symbols) a second. */
static inline float dec_angle_hz(float angle, float rate)
{
	return angle * rate / 65536.0f;
}

/* dB relative to the receiver's full scale, times 10, of a power in output units squared. */
static inline int16_t dec_dbfs_x10(float power)
{
	float db;

	if (power <= 0.0f) {
		return -32768;
	}
	db = 100.0f * log10f(power / (DEC_FULL_SCALE * DEC_FULL_SCALE));
	if (db < -32767.0f) {
		return -32767;
	}
	if (db > 32767.0f) {
		return 32767;
	}
	return (int16_t)lrintf(db);
}

#endif /* DEC_UTIL_H_ */
```

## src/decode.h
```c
/*
 * SPDX-License-Identifier: GPL-3.0-or-later
 *
 * The decoders that run over a closed burst (doc/pcap.md, "Decoders"): Bluetooth LE
 * (dec_ble.c), IEEE 802.15.4 (dec_wpan.c) and the generic analysis (dec_generic.c). Plain C, no
 * Zephyr: each is unit tested on native_sim. Each takes a burst (burst.h), a scratch area the
 * caller owns and hands its packets to a callback; none keeps a pointer into the burst or the
 * scratch after it returns.
 */

#ifndef DECODE_H_
#define DECODE_H_

#include <stdbool.h>
#include <stddef.h>
#include <stdint.h>

#include "burst.h"
#include "pcap_proto.h"

/* ---- Bluetooth LE ---- */

#define DEC_BLE_ADV_AA       0x8E89BED6U
#define DEC_BLE_ADV_CRC_INIT 0x555555U
/* Access addresses looked for at once: the advertising one and those added. */
#define DEC_BLE_AA_MAX 8U
/* Longest on-air packet: access address, header, 255 bytes of payload, CRC. */
#define DEC_BLE_AIR_MAX (4U + 2U + 255U + 3U)

enum dec_ble_phy {
	DEC_BLE_PHY_1M = 0,
	DEC_BLE_PHY_2M = 1,
};

struct dec_ble_aa {
	uint32_t aa;
	/* 0: unknown, the CRC is not checked. */
	uint32_t crc_init;
};

struct dec_ble_cfg {
	struct dec_ble_aa aa[DEC_BLE_AA_MAX];
	uint8_t aa_count;
	/* Access address bit errors tolerated (0 to 2). */
	uint8_t max_errors;
	/* Try LE 2M too (only at 4 MS/s); skip LE 1M (a burst too wide for it, tried for LE 2M). */
	bool phy_2m, skip_1m;
	/* Packets with a failing CRC are emitted too. */
	bool keep_bad;
};

struct dec_ble_pkt {
	enum dec_ble_phy phy;
	/* The access address matched (as configured) and its bit errors. */
	uint32_t aa;
	uint8_t aa_errors;
	bool crc_checked, crc_ok;
	/* On-air bytes from the access address on: aa, header, payload, CRC. */
	uint16_t len;
	uint8_t air[DEC_BLE_AIR_MAX];
	/* The first preamble sample's index in the burst (may be negative: before it). */
	int32_t start;
	/* Carrier offset, Hz. */
	int32_t offset_hz;
	/* Mean power over the packet, output units squared. */
	float power;
	/* A CONNECT_IND: the access address and CRCInit it announces (0, 0 otherwise). */
	uint32_t conn_aa, conn_crc_init;
};

typedef void (*dec_ble_emit)(const struct dec_ble_pkt *pkt, void *user);

/* Scratch bytes dec_ble_run() needs for a burst of @p n samples. */
size_t dec_ble_scratch(uint32_t n);

/*
 * Every packet in the burst (rate 4 MS/s or 2 MS/s: else -ENOTSUP). Returns the count, or a
 * negative errno (-ENOMEM if @p scratch is short).
 */
int dec_ble_run(const struct burst *b, const struct dec_ble_cfg *cfg, void *scratch,
		size_t scratch_len, dec_ble_emit emit, void *user);

/* The RF channel of the LINKTYPE 256 header (0 at 2402 MHz, 39 at 2480) of a frequency. */
int dec_ble_rf_channel(uint64_t freq_hz);

/* ---- IEEE 802.15.4 ---- */

struct dec_wpan_cfg {
	bool keep_bad;
	/*
	 * If not NULL: where the run leaves the most preamble symbols in a row the stream held
	 * (ieee154_phy_rx_preamble_run_i(), 0 to 4), a whole frame or not. Untouched by a run that
	 * has no stream to read.
	 */
	uint8_t *preamble_run;
};

struct dec_wpan_pkt {
	/* The PSDU with its FCS. */
	uint8_t len;
	uint8_t psdu[127];
	bool fcs_ok;
	/* 0 to 255 from the chip errors, as the PHY reports it. */
	uint8_t lqi;
	/* The first preamble sample's index in the burst (may be negative). */
	int32_t start;
	int32_t offset_hz;
	float power;
	/* The 802.15.4 channel (11 to 26) of the frequency decoded on, 0 off the grid. */
	uint8_t channel;
	/* Decoded from the combination of two neighbouring channels. */
	bool combined;
};

typedef void (*dec_wpan_emit)(const struct dec_wpan_pkt *pkt, void *user);

size_t dec_wpan_scratch(uint32_t n);

/*
 * Every frame in the burst (rate 4 MS/s, or 2 MS/s read at 4 MS/s, the odd samples interpolated:
 * else -ENOTSUP). Returns the count or a negative errno.
 */
int dec_wpan_run(const struct burst *b, const struct dec_wpan_cfg *cfg, void *scratch,
		 size_t scratch_len, dec_wpan_emit emit, void *user);

/*
 * The band between two neighbouring channels (@p lo's index one below @p hi's, both at
 * 4 MS/s) over the frames both hold, combined as doc/pcap.md describes, through the PHY.
 * Packets carry the middle frequency. Returns the count or a negative errno.
 */
int dec_wpan_run_pair(const struct burst *lo, const struct burst *hi,
		      const struct dec_wpan_cfg *cfg, void *scratch, size_t scratch_len,
		      dec_wpan_emit emit, void *user);

/* The 802.15.4 channel of a frequency on the 2.4 GHz grid (2405 + 5 (c - 11) MHz), else 0. */
int dec_wpan_channel(uint64_t freq_hz);
/* The frequency of 802.15.4 channel @p channel (11 to 26), else 0. */
uint64_t dec_wpan_freq(int channel);

/* ---- generic ---- */

struct dec_generic_cfg {
	/* Bits emitted at most (0, or above PCAP_BURST_BITS_MAX: PCAP_BURST_BITS_MAX). */
	uint16_t max_bits;
	/*
	 * Samples of the (trimmed) loud part analysed at most, from its start (0: all of them);
	 * duration_us, power and peak still cover the whole loud part.
	 */
	uint32_t max_samples;
};

struct dec_generic_out {
	/*
	 * The record's header, every field but version and hdr_len (left 0: the writer's) filled
	 * in: rx_gain, channel and channels copied from the burst, its BURST_F_* flags mapped to
	 * PCAP_BF_*, PCAP_BF_BITS added when bits were sliced. bandwidth_hz and offset_hz are 0
	 * when nothing stood clear of the noise.
	 */
	struct pcap_burst_hdr hdr;
	/*
	 * hdr.nbits bits, MSB first, the rest zero: one a symbol (FSK and MSK: 1 above the centre;
	 * OOK: 1 on; DBPSK: 1 for a phase step of pi), two a symbol of 4FSK (the sign, then 1 for
	 * an inner tone) and of DQPSK (steps of 0, pi / 2, pi, -pi / 2 as 00, 01, 11, 10).
	 */
	uint8_t bits[PCAP_BURST_BITS_MAX / 8U];
	/* The loud part's first sample's index in the burst (trimmed: the record's time). */
	uint32_t start;
};

/* Scratch bytes dec_generic_run() needs for a burst of @p n samples (some 4 n + 41 KiB). */
size_t dec_generic_scratch(uint32_t n);

/*
 * The analysis of a burst at any rate (dec_generic.c); @p cfg may be NULL. A burst without
 * samples (a wideband record's) gets its metadata only. 0, -EINVAL without a burst or @p out,
 * -ENOMEM when @p scratch is short.
 */
int dec_generic_run(const struct burst *b, const struct dec_generic_cfg *cfg, void *scratch,
		    size_t scratch_len, struct dec_generic_out *out);

#endif /* DECODE_H_ */
```

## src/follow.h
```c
/*
 * SPDX-License-Identifier: GPL-3.0-or-later
 *
 * The follow mode's decisions (doc/pcap.md, "Modes"): from the survey to the 802.15.4 channel it
 * sighted, back when that channel goes quiet. Plain C on times the caller passes:
 * tests/unit/pcap_follow runs it on native_sim. The caller holds a lock around these.
 */

#ifndef FOLLOW_H_
#define FOLLOW_H_

#include <stdbool.h>
#include <stdint.h>

#define FOLLOW_CHANNEL_FIRST 11
#define FOLLOW_CHANNELS      16U
/*
 * Points on a channel that make the survey go there: a sure sighting has them, a doubtful one a
 * part of them.
 */
#define FOLLOW_SIGHT_POINTS  2U
/* A stay ends after this many times channel_ms, however busy the channel: the survey's turn. */
#define FOLLOW_STAY_MAX      4U
/* How often the survey looks with nothing sighted (a sighting wakes it at once). */
#define FOLLOW_IDLE_MS       1000U

enum follow_act {
	FOLLOW_STAY,
	FOLLOW_TO_CHANNEL,
	FOLLOW_TO_SURVEY,
};

struct follow {
	uint32_t survey_ms, channel_ms;
	/* When this survey or stay began, and the stay's last frame. */
	uint32_t since, last;
	/* This survey's points per channel, and the channel of the newest sighting. */
	uint16_t sights[FOLLOW_CHANNELS];
	uint8_t newest;
	/* The channel of this stay; 0 in the survey. The channel of the last stay. */
	uint8_t channel, previous;
};

/* In the survey from @p now_ms on, for at least @p survey_ms; a stay ends @p channel_ms after its
 * last frame.
 */
void follow_init(struct follow *f, uint32_t survey_ms, uint32_t channel_ms, uint32_t now_ms);

/*
 * The decoder found 802.15.4 on @p channel, worth @p points, in a burst of the survey or of the
 * channel mode: the other mode's bursts, still queued after a switch, do not count, and any
 * burst of the channel followed extends a stay. Returns whether follow_step() may have something
 * to do at once.
 */
bool follow_sight(struct follow *f, int channel, uint32_t points, bool from_survey,
		  uint32_t now_ms);

/*
 * What to do at @p now_ms; f->channel then says where to. @p wait_ms: when to ask again, at the
 * latest.
 */
enum follow_act follow_step(struct follow *f, uint32_t now_ms, uint32_t *wait_ms);

#endif /* FOLLOW_H_ */
```
